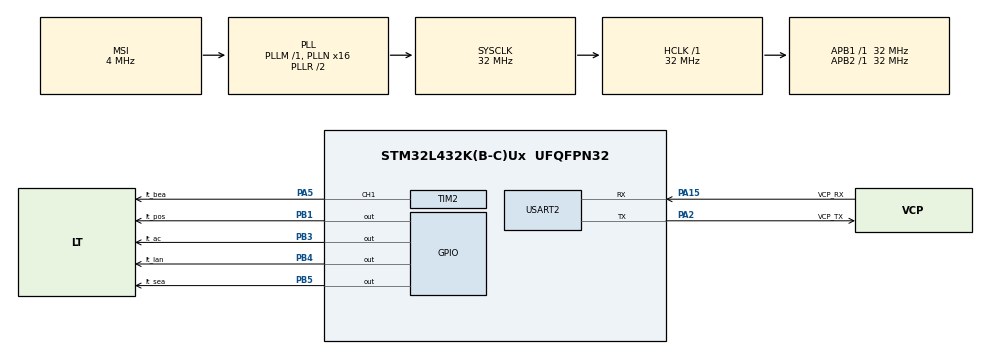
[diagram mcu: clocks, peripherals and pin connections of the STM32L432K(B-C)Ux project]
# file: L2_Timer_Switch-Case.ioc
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Dma.Request0=TIM2_CH1
Dma.TIM2_CH1.0.Direction=DMA_MEMORY_TO_PERIPH
Dma.TIM2_CH1.0.Instance=DMA1_Channel5
Dma.TIM2_CH1.0.MemDataAlignment=DMA_MDATAALIGN_WORD
Dma.TIM2_CH1.0.MemInc=DMA_MINC_ENABLE
Dma.TIM2_CH1.0.Mode=DMA_CIRCULAR
Dma.TIM2_CH1.0.PeriphDataAlignment=DMA_PDATAALIGN_WORD
Dma.TIM2_CH1.0.PeriphInc=DMA_PINC_DISABLE
Dma.TIM2_CH1.0.Priority=DMA_PRIORITY_LOW
Mcu.Family=STM32L4
Mcu.Name=STM32L432K(B-C)Ux
Mcu.Package=UFQFPN32
NVIC.DMA1_Channel5_IRQn=true\:0\:0\:false\:false\:true\:false\:true\:true
NVIC.PriorityGroup=NVIC_PRIORITYGROUP_4
NVIC.TIM1_UP_TIM16_IRQn=true\:0\:0\:false\:false\:true\:true\:true\:true
PA0.GPIO_Label=MCO [High speed clock in]
PA0.Mode=HSE-External-Clock-Source-for-LittleOrca
PA0.Signal=RCC_CK_IN
PA13\ (JTMS-SWDIO).GPIO_Label=SWDIO
PA13\ (JTMS-SWDIO).Mode=Serial_Wire
PA13\ (JTMS-SWDIO).Signal=SYS_JTMS-SWDIO
PA14\ (JTCK-SWCLK).GPIO_Label=SWCLK
PA14\ (JTCK-SWCLK).Mode=Serial_Wire
PA14\ (JTCK-SWCLK).Signal=SYS_JTCK-SWCLK
PA15\ (JTDI).GPIO_Label=VCP_RX
PA15\ (JTDI).Mode=Asynchronous
PA15\ (JTDI).Signal=USART2_RX
PA2.GPIO_Label=VCP_TX
PA2.Mode=Asynchronous
PA2.Signal=USART2_TX
PA5.GPIO_Label=lt_bea
PA5.Signal=S_TIM2_CH1
PB1.GPIO_Label=lt_pos
PB1.Signal=GPIO_Output
PB3\ (JTDO-TRACESWO).GPIO_Label=lt_ac
PB3\ (JTDO-TRACESWO).Signal=GPIO_Output
PB4\ (NJTRST).GPIO_Label=lt_lan
PB4\ (NJTRST).Signal=GPIO_Output
PB5.GPIO_Label=lt_sea
PB5.Signal=GPIO_Output
PC14-OSC32_IN\ (PC14).Mode=LSE-External-Oscillator
PC14-OSC32_IN\ (PC14).Signal=RCC_OSC32_IN
PC15-OSC32_OUT\ (PC15).Mode=LSE-External-Oscillator
PC15-OSC32_OUT\ (PC15).Signal=RCC_OSC32_OUT
ProjectManager.HeapSize=0x200
ProjectManager.StackSize=0x400
ProjectManager.TargetToolchain=STM32CubeIDE
RCC.AHBFreq_Value=32000000
RCC.APB1Freq_Value=32000000
RCC.APB1TimFreq_Value=32000000
RCC.APB2Freq_Value=32000000
RCC.APB2TimFreq_Value=32000000
RCC.CortexFreq_Value=32000000
RCC.HCLKFreq_Value=32000000
RCC.HSE_VALUE=8000000
RCC.HSI16_VALUE=16000000
RCC.HSI48_VALUE=48000000
RCC.HSI_VALUE=16000000
RCC.MSI_VALUE=4000000
RCC.PLLMUL=RCC_PLLMUL_4
RCC.PLLN=16
RCC.SYSCLKFreq_VALUE=32000000
RCC.SYSCLKSource=RCC_SYSCLKSOURCE_PLLCLK
RCC.VCOOutputFreq_Value=64000000
SH.S_TIM2_CH1.0=TIM2_CH1,PWM Generation1 CH1
TIM1.Period=5000-1
TIM1.Prescaler=320-1
TIM2.Channel-PWM\ Generation1\ CH1=TIM_CHANNEL_1
TIM2.OCFastMode_PWM-PWM\ Generation1\ CH1=TIM_OCFAST_DISABLE
TIM2.Period=11000-1
TIM2.Prescaler=32-1
USART2.VirtualMode-Asynchronous=VM_ASYNC
VP_TIM1_VS_ClockSourceINT.Mode=Internal
VP_TIM2_VS_ClockSourceINT.Mode=Internal
board=NUCLEO-L432KC

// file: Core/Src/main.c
/* USER CODE BEGIN Header */
/**
  ******************************************************************************
  * @file           : main.c
  * @brief          : Main program body
  ******************************************************************************
  * @attention
  *
  * Copyright (c) 2024 STMicroelectronics.
  * All rights reserved.
  *
  * This software is licensed under terms that can be found in the LICENSE file
  * in the root directory of this software component.
  * If no LICENSE file comes with this software, it is provided AS-IS.
  *
  ******************************************************************************
  */

  /*--------------------------------------------------------------------------
   * Task:
   * - create light system for aircraft
   *	-> Beacon lights
   *	-> Position Lights
   *	-> Anti Collition Lights
   *	-> Landing Light
   *	-> Search light
   *
   * - Dev. Board: NUCLEO-L432KC
   * - User Manual: UM1884
   *   https://www.st.com/resource/en/user_manual/um1884-description-of-stm32l4l4-hal-and-lowlayer-drivers-stmicroelectronics.pdf
   * - STM32L4 Timers
   *   https://www.st.com/resource/en/product_training/STM32L4_WDG_TIMERS_GPTIM.pdf
   *--------------------------------------------------------------------------
   */

/* USER CODE END Header */
#include "main.h"
#include "dma.h"
#include "tim.h"
#include "usart.h"
#include "gpio.h"

/* USER CODE BEGIN Includes */
#include <my_controls.h>
/* USER CODE END Includes */

void SystemClock_Config(void);

int main(void)
{

  /* MCU Configuration--------------------------------------------------------*/

  /* Reset of all peripherals, Initializes the Flash interface and the Systick. */
  HAL_Init();

  /* USER CODE BEGIN Init */
  init_status(true, false, false, false, false);
  /* USER CODE END Init */

  /* Configure the system clock */
  SystemClock_Config();

  /* Initialize all configured peripherals */
  MX_GPIO_Init();
  MX_DMA_Init();
  MX_USART2_UART_Init();
  MX_TIM1_Init();
  MX_TIM2_Init();
  /* USER CODE BEGIN 2 */
  HAL_TIM_Base_Start_IT(&htim1);
  /* USER CODE END 2 */

  /* Infinite loop */
  /* USER CODE BEGIN WHILE */
  while (1)
  {
	  lt_beacon();
	  lt_position();
	  lt_anticollition();
	  lt_landing();
	  lt_search();

    /* USER CODE END WHILE */

  }
}

void SystemClock_Config(void)
{
  RCC_OscInitTypeDef RCC_OscInitStruct = {0};
  RCC_ClkInitTypeDef RCC_ClkInitStruct = {0};

  /** Configure the main internal regulator output voltage
  */
  if (HAL_PWREx_ControlVoltageScaling(PWR_REGULATOR_VOLTAGE_SCALE1) != HAL_OK)
  {
    Error_Handler();
  }

  /** Configure LSE Drive Capability
  */
  HAL_PWR_EnableBkUpAccess();
  __HAL_RCC_LSEDRIVE_CONFIG(RCC_LSEDRIVE_LOW);

  /** Initializes the RCC Oscillators according to the specified parameters
  * in the RCC_OscInitTypeDef structure.
  */
  RCC_OscInitStruct.OscillatorType = RCC_OSCILLATORTYPE_LSE|RCC_OSCILLATORTYPE_MSI;
  RCC_OscInitStruct.LSEState = RCC_LSE_ON;
  RCC_OscInitStruct.MSIState = RCC_MSI_ON;
  RCC_OscInitStruct.MSICalibrationValue = 0;
  RCC_OscInitStruct.MSIClockRange = RCC_MSIRANGE_6;
  RCC_OscInitStruct.PLL.PLLState = RCC_PLL_ON;
  RCC_OscInitStruct.PLL.PLLSource = RCC_PLLSOURCE_MSI;
  RCC_OscInitStruct.PLL.PLLM = 1;
  RCC_OscInitStruct.PLL.PLLN = 16;
  RCC_OscInitStruct.PLL.PLLP = RCC_PLLP_DIV7;
  RCC_OscInitStruct.PLL.PLLQ = RCC_PLLQ_DIV2;
  RCC_OscInitStruct.PLL.PLLR = RCC_PLLR_DIV2;
  if (HAL_RCC_OscConfig(&RCC_OscInitStruct) != HAL_OK)
  {
    Error_Handler();
  }

  /** Initializes the CPU, AHB and APB buses clocks
  */
  RCC_ClkInitStruct.ClockType = RCC_CLOCKTYPE_HCLK|RCC_CLOCKTYPE_SYSCLK
                              |RCC_CLOCKTYPE_PCLK1|RCC_CLOCKTYPE_PCLK2;
  RCC_ClkInitStruct.SYSCLKSource = RCC_SYSCLKSOURCE_PLLCLK;
  RCC_ClkInitStruct.AHBCLKDivider = RCC_SYSCLK_DIV1;
  RCC_ClkInitStruct.APB1CLKDivider = RCC_HCLK_DIV1;
  RCC_ClkInitStruct.APB2CLKDivider = RCC_HCLK_DIV1;

  if (HAL_RCC_ClockConfig(&RCC_ClkInitStruct, FLASH_LATENCY_1) != HAL_OK)
  {
    Error_Handler();
  }

  /** Enable MSI Auto calibration
  */
  HAL_RCCEx_EnableMSIPLLMode();
}

/* USER CODE BEGIN 4 */
HAL_TIM_PeriodElapsedCallback(TIM_HandleTypeDef *htim)
{
	if (htim->Instance == TIM1)
	{
		counter();
	}
}
/* USER CODE END 4 */

void Error_Handler(void)
{
  __disable_irq();
  while (1)
  {
  }
}
